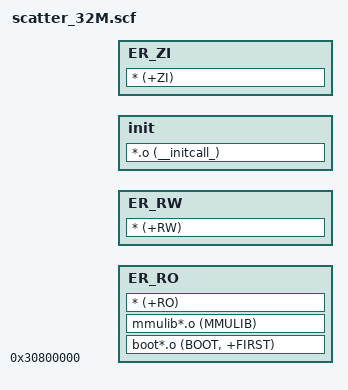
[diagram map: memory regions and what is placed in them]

LR_1 0x30800000
{
    ER_RO +0 
    {
        boot*.o (BOOT, +FIRST)    
        mmulib*.o (MMULIB)  
        * (+RO)
    }

    ER_RW +0 
    {
        * (+RW)
    }
    
    init +0x0
    {
        *.o (__initcall_)
    }
        
    ER_ZI +0 
    {   
        * (+ZI)
    }    
}

